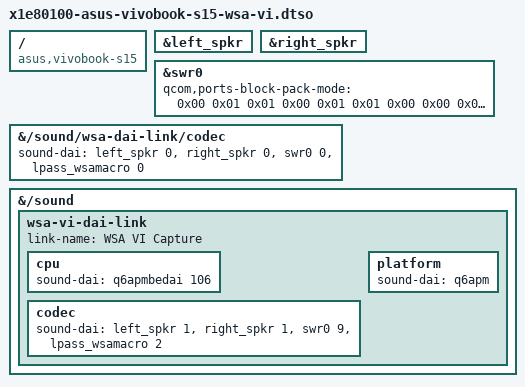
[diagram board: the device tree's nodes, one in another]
// SPDX-License-Identifier: GPL-2.0-only
/*
 * WSA884x V/I sense feedback for the Asus Vivobook S15 (S5507QA).
 *
 * - "WSA VI Capture" BE link: WSA_CODEC_DMA_TX_0 <- wsa_macro AIF_VI <- both amplifiers'
 *   VISENSE ports (SoundWire master ports 10/11).
 * - wsa884x gets a second DAI (0 = SPKR playback, 1 = SPKR VI capture), see kernel/0002.
 * - VISENSE on wsa884x is a simple data port without BlockCtrl3, so it always uses per-port
 *   block packing: set the same on the master for ports 10/11 (otherwise V/I is garbage).
 */
/dts-v1/;
/plugin/;

/ { compatible = "asus,vivobook-s15"; };

&left_spkr { #sound-dai-cells = <1>; };
&right_spkr { #sound-dai-cells = <1>; };

&swr0 {
	qcom,ports-block-pack-mode = /bits/ 8 <0x00 0x01 0x01 0x00 0x01 0x01 0x00
					       0x00 0x00 0x00 0x00 0x00 0x00>;
};

&{/sound/wsa-dai-link/codec} {
	sound-dai = <&left_spkr 0>, <&right_spkr 0>, <&swr0 0>, <&lpass_wsamacro 0>;
};

&{/sound} {
	wsa-vi-dai-link {
		link-name = "WSA VI Capture";
		cpu { sound-dai = <&q6apmbedai 106>; };	/* WSA_CODEC_DMA_TX_0 */
		/* wsa884x VI DAIs, first SoundWire din DAI (Pin9), wsa_macro AIF_VI */
		codec { sound-dai = <&left_spkr 1>, <&right_spkr 1>, <&swr0 9>, <&lpass_wsamacro 2>; };
		platform { sound-dai = <&q6apm>; };
	};
};
